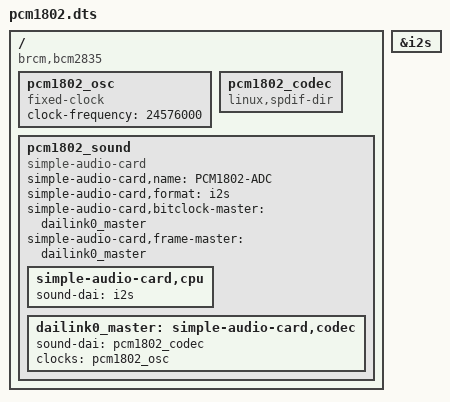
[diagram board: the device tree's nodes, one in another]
/dts-v1/;
/plugin/;

/ {
    compatible = "brcm,bcm2835";

    fragment@0 {
        target-path = "/";
        __overlay__ {
            pcm1802_osc: pcm1802_osc {
                compatible = "fixed-clock";
                #clock-cells = <0>;
                clock-frequency = <24576000>;
            };

            pcm1802_codec: pcm1802_codec {
                #sound-dai-cells = <0>;
                compatible = "linux,spdif-dir";
                status = "okay";
            };

            pcm1802_sound: pcm1802_sound {
                compatible = "simple-audio-card";
                simple-audio-card,name = "PCM1802-ADC";
                simple-audio-card,format = "i2s";
                
                simple-audio-card,bitclock-master = <&dailink0_master>;
                simple-audio-card,frame-master = <&dailink0_master>;

                simple-audio-card,cpu {
                    sound-dai = <&i2s>;
                };

                dailink0_master: simple-audio-card,codec {
                    sound-dai = <&pcm1802_codec>;
                    clocks = <&pcm1802_osc>;
                };
            };
        };
    };

    /* Force the existing I2S controller to 'okay' and add cell-definition */
    fragment@1 {
        target = <&i2s>;
        __overlay__ {
            #sound-dai-cells = <0>;
            status = "okay";
        };
    };
};
